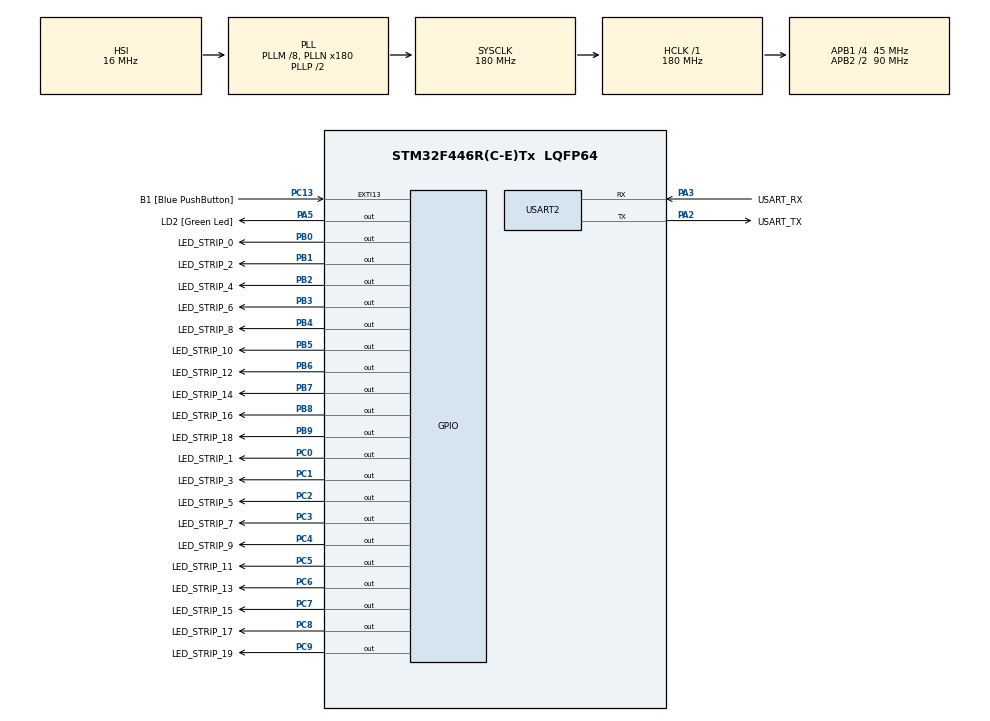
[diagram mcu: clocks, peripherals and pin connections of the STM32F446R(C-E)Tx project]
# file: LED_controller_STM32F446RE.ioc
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Dma.Request0=USART2_RX
Dma.Request1=USART2_TX
Dma.USART2_RX.0.Direction=DMA_PERIPH_TO_MEMORY
Dma.USART2_RX.0.FIFOMode=DMA_FIFOMODE_DISABLE
Dma.USART2_RX.0.Instance=DMA1_Stream5
Dma.USART2_RX.0.MemDataAlignment=DMA_MDATAALIGN_BYTE
Dma.USART2_RX.0.MemInc=DMA_MINC_ENABLE
Dma.USART2_RX.0.Mode=DMA_NORMAL
Dma.USART2_RX.0.PeriphDataAlignment=DMA_PDATAALIGN_BYTE
Dma.USART2_RX.0.PeriphInc=DMA_PINC_DISABLE
Dma.USART2_RX.0.Priority=DMA_PRIORITY_VERY_HIGH
Dma.USART2_TX.1.Direction=DMA_MEMORY_TO_PERIPH
Dma.USART2_TX.1.FIFOMode=DMA_FIFOMODE_DISABLE
Dma.USART2_TX.1.Instance=DMA1_Stream6
Dma.USART2_TX.1.MemDataAlignment=DMA_MDATAALIGN_BYTE
Dma.USART2_TX.1.MemInc=DMA_MINC_ENABLE
Dma.USART2_TX.1.Mode=DMA_NORMAL
Dma.USART2_TX.1.PeriphDataAlignment=DMA_PDATAALIGN_BYTE
Dma.USART2_TX.1.PeriphInc=DMA_PINC_DISABLE
Dma.USART2_TX.1.Priority=DMA_PRIORITY_VERY_HIGH
FREERTOS.Tasks01=defaultTask,0,128,StartDefaultTask,Default,NULL,Dynamic,NULL,NULL
FREERTOS.configCHECK_FOR_STACK_OVERFLOW=1
FREERTOS.configGENERATE_RUN_TIME_STATS=1
FREERTOS.configQUEUE_REGISTRY_SIZE=40
Mcu.Family=STM32F4
Mcu.Name=STM32F446R(C-E)Tx
Mcu.Package=LQFP64
NVIC.DMA1_Stream5_IRQn=true\:5\:0\:false\:false\:true\:true\:false\:true
NVIC.DMA1_Stream6_IRQn=true\:5\:0\:false\:false\:true\:true\:false\:true
NVIC.PriorityGroup=NVIC_PRIORITYGROUP_4
NVIC.TIM3_IRQn=true\:5\:0\:true\:false\:true\:true\:true\:true
NVIC.TIM4_IRQn=true\:0\:0\:false\:false\:true\:false\:false\:true
NVIC.TimeBase=TIM4_IRQn
NVIC.TimeBaseIP=TIM4
PA13.GPIO_Label=TMS
PA13.Mode=Serial_Wire
PA13.Signal=SYS_JTMS-SWDIO
PA14.GPIO_Label=TCK
PA14.Mode=Serial_Wire
PA14.Signal=SYS_JTCK-SWCLK
PA2.GPIO_Label=USART_TX
PA2.Mode=Asynchronous
PA2.Signal=USART2_TX
PA3.GPIO_Label=USART_RX
PA3.Mode=Asynchronous
PA3.Signal=USART2_RX
PA5.GPIO_Label=LD2 [Green Led]
PA5.Signal=GPIO_Output
PB0.GPIO_Label=LED_STRIP_0
PB0.Signal=GPIO_Output
PB1.GPIO_Label=LED_STRIP_2
PB1.Signal=GPIO_Output
PB2.GPIO_Label=LED_STRIP_4
PB2.Signal=GPIO_Output
PB3.GPIO_Label=LED_STRIP_6
PB3.Signal=GPIO_Output
PB4.GPIO_Label=LED_STRIP_8
PB4.Signal=GPIO_Output
PB5.GPIO_Label=LED_STRIP_10
PB5.Signal=GPIO_Output
PB6.GPIO_Label=LED_STRIP_12
PB6.Signal=GPIO_Output
PB7.GPIO_Label=LED_STRIP_14
PB7.Signal=GPIO_Output
PB8.GPIO_Label=LED_STRIP_16
PB8.Signal=GPIO_Output
PB9.GPIO_Label=LED_STRIP_18
PB9.Signal=GPIO_Output
PC0.GPIO_Label=LED_STRIP_1
PC0.Signal=GPIO_Output
PC1.GPIO_Label=LED_STRIP_3
PC1.Signal=GPIO_Output
PC13.GPIO_Label=B1 [Blue PushButton]
PC13.GPIO_ModeDefaultEXTI=GPIO_MODE_IT_FALLING
PC13.Signal=GPXTI13
PC2.GPIO_Label=LED_STRIP_5
PC2.Signal=GPIO_Output
PC3.GPIO_Label=LED_STRIP_7
PC3.Signal=GPIO_Output
PC4.GPIO_Label=LED_STRIP_9
PC4.Signal=GPIO_Output
PC5.GPIO_Label=LED_STRIP_11
PC5.Signal=GPIO_Output
PC6.GPIO_Label=LED_STRIP_13
PC6.Signal=GPIO_Output
PC7.GPIO_Label=LED_STRIP_15
PC7.Signal=GPIO_Output
PC8.GPIO_Label=LED_STRIP_17
PC8.Signal=GPIO_Output
PC9.GPIO_Label=LED_STRIP_19
PC9.Signal=GPIO_Output
ProjectManager.HeapSize=0x200
ProjectManager.StackSize=0x400
ProjectManager.TargetToolchain=STM32CubeIDE
RCC.48MHZClocksFreq_Value=84000000
RCC.AHBFreq_Value=180000000
RCC.APB1CLKDivider=RCC_HCLK_DIV4
RCC.APB1Freq_Value=45000000
RCC.APB1TimFreq_Value=90000000
RCC.APB2CLKDivider=RCC_HCLK_DIV2
RCC.APB2Freq_Value=90000000
RCC.APB2TimFreq_Value=180000000
RCC.CortexFreq_Value=180000000
RCC.FLatency-AdvancedSettings=FLASH_LATENCY_5
RCC.HCLKFreq_Value=180000000
RCC.HSE_VALUE=8000000
RCC.HSI_VALUE=16000000
RCC.PLLM=8
RCC.PLLN=180
RCC.SYSCLKFreq_VALUE=180000000
RCC.SYSCLKSource=RCC_SYSCLKSOURCE_PLLCLK
RCC.USBFreq_Value=180000000
RCC.VCOOutputFreq_Value=360000000
TIM3.Period=79
TIM3.Prescaler=44999
USART2.VirtualMode=VM_ASYNC
VP_FREERTOS_VS_CMSIS_V1.Mode=CMSIS_V1
VP_SYS_VS_tim4.Mode=TIM4
VP_TIM3_VS_ClockSourceINT.Mode=Internal
board=NUCLEO-F446RE

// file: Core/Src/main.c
/* USER CODE BEGIN Header */
/**
  ******************************************************************************
  * @file           : main.c
  * @brief          : Main program body
  ******************************************************************************
  * @attention
  *
  * <h2><center>&copy; Copyright (c) 2020 STMicroelectronics.
  * All rights reserved.</center></h2>
  *
  * This software component is licensed by ST under Ultimate Liberty license
  * SLA0044, the "License"; You may not use this file except in compliance with
  * the License. You may obtain a copy of the License at:
  *                             www.st.com/SLA0044
  *
  ******************************************************************************
  */
/* USER CODE END Header */
#include "main.h"
#include "cmsis_os.h"
#include "dma.h"
#include "tim.h"
#include "usart.h"
#include "gpio.h"

/* USER CODE BEGIN Includes */
#include "porting_layer.h"
#include "ws2812b_multi_strip_driver.h"
/* USER CODE END Includes */

void SystemClock_Config(void);
void MX_FREERTOS_Init(void);

int main(void)
{

  /* MCU Configuration--------------------------------------------------------*/

  /* Reset of all peripherals, Initializes the Flash interface and the Systick. */
  HAL_Init();

  /* Configure the system clock */
  SystemClock_Config();

  /* Initialize all configured peripherals */
  MX_GPIO_Init();
  MX_DMA_Init();
  MX_USART2_UART_Init();
  MX_TIM3_Init();

  /* Call init function for freertos objects (in freertos.c) */
  MX_FREERTOS_Init();
  /* Start scheduler */
  osKernelStart();

  /* We should never get here as control is now taken by the scheduler */
  /* Infinite loop */
  while (1)
  {

  }
}

void SystemClock_Config(void)
{
  RCC_OscInitTypeDef RCC_OscInitStruct = {0};
  RCC_ClkInitTypeDef RCC_ClkInitStruct = {0};

  /** Configure the main internal regulator output voltage
  */
  __HAL_RCC_PWR_CLK_ENABLE();
  __HAL_PWR_VOLTAGESCALING_CONFIG(PWR_REGULATOR_VOLTAGE_SCALE1);
  /** Initializes the RCC Oscillators according to the specified parameters
  * in the RCC_OscInitTypeDef structure.
  */
  RCC_OscInitStruct.OscillatorType = RCC_OSCILLATORTYPE_HSI;
  RCC_OscInitStruct.HSIState = RCC_HSI_ON;
  RCC_OscInitStruct.HSICalibrationValue = RCC_HSICALIBRATION_DEFAULT;
  RCC_OscInitStruct.PLL.PLLState = RCC_PLL_ON;
  RCC_OscInitStruct.PLL.PLLSource = RCC_PLLSOURCE_HSI;
  RCC_OscInitStruct.PLL.PLLM = 8;
  RCC_OscInitStruct.PLL.PLLN = 180;
  RCC_OscInitStruct.PLL.PLLP = RCC_PLLP_DIV2;
  RCC_OscInitStruct.PLL.PLLQ = 2;
  RCC_OscInitStruct.PLL.PLLR = 2;
  if (HAL_RCC_OscConfig(&RCC_OscInitStruct) != HAL_OK)
  {
    Error_Handler();
  }
  /** Activate the Over-Drive mode
  */
  if (HAL_PWREx_EnableOverDrive() != HAL_OK)
  {
    Error_Handler();
  }
  /** Initializes the CPU, AHB and APB buses clocks
  */
  RCC_ClkInitStruct.ClockType = RCC_CLOCKTYPE_HCLK|RCC_CLOCKTYPE_SYSCLK
                              |RCC_CLOCKTYPE_PCLK1|RCC_CLOCKTYPE_PCLK2;
  RCC_ClkInitStruct.SYSCLKSource = RCC_SYSCLKSOURCE_PLLCLK;
  RCC_ClkInitStruct.AHBCLKDivider = RCC_SYSCLK_DIV1;
  RCC_ClkInitStruct.APB1CLKDivider = RCC_HCLK_DIV4;
  RCC_ClkInitStruct.APB2CLKDivider = RCC_HCLK_DIV2;

  if (HAL_RCC_ClockConfig(&RCC_ClkInitStruct, FLASH_LATENCY_5) != HAL_OK)
  {
    Error_Handler();
  }
}

void HAL_TIM_PeriodElapsedCallback(TIM_HandleTypeDef *htim)
{
  if (htim->Instance == TIM4) {
    HAL_IncTick();
  }
  /* USER CODE BEGIN Callback 1 */
  else if (htim->Instance == TIM3)
  {
      pl_start_frame_timer();
      start_led_driver_run();
  }
  /* USER CODE END Callback 1 */
}

void Error_Handler(void)
{
}

/************************ (C) COPYRIGHT STMicroelectronics *****END OF FILE****/

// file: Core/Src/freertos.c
/* USER CODE BEGIN Header */
/**
  ******************************************************************************
  * File Name          : freertos.c
  * Description        : Code for freertos applications
  ******************************************************************************
  * @attention
  *
  * <h2><center>&copy; Copyright (c) 2020 STMicroelectronics.
  * All rights reserved.</center></h2>
  *
  * This software component is licensed by ST under Ultimate Liberty license
  * SLA0044, the "License"; You may not use this file except in compliance with
  * the License. You may obtain a copy of the License at:
  *                             www.st.com/SLA0044
  *
  ******************************************************************************
  */
/* USER CODE END Header */

#include "FreeRTOS.h"
#include "task.h"
#include "main.h"
#include "cmsis_os.h"

/* USER CODE BEGIN Includes */
#include "ws2812b_multi_strip_driver.h"
#include "shows.h"
#include "scheduler.h"
/* USER CODE END Includes */

osThreadId defaultTaskHandle;

void StartDefaultTask(void const * argument);

void MX_FREERTOS_Init(void); /* (MISRA C 2004 rule 8.1) */

/* GetIdleTaskMemory prototype (linked to static allocation support) */
void vApplicationGetIdleTaskMemory( StaticTask_t **ppxIdleTaskTCBBuffer, StackType_t **ppxIdleTaskStackBuffer, uint32_t *pulIdleTaskStackSize );

/* Hook prototypes */
void configureTimerForRunTimeStats(void);
unsigned long getRunTimeCounterValue(void);
void vApplicationStackOverflowHook(xTaskHandle xTask, signed char *pcTaskName);

/* USER CODE BEGIN 1 */
/* Functions needed when configGENERATE_RUN_TIME_STATS is on */
__weak void configureTimerForRunTimeStats(void)
{

}

__weak unsigned long getRunTimeCounterValue(void)
{
return 0;
}
/* USER CODE END 1 */

/* USER CODE BEGIN 4 */
__weak void vApplicationStackOverflowHook(xTaskHandle xTask, signed char *pcTaskName)
{
   /* Run time stack overflow checking is performed if
   configCHECK_FOR_STACK_OVERFLOW is defined to 1 or 2. This hook function is
   called if a stack overflow is detected. */
}
/* USER CODE END 4 */

/* USER CODE BEGIN GET_IDLE_TASK_MEMORY */
static StaticTask_t xIdleTaskTCBBuffer;
static StackType_t xIdleStack[configMINIMAL_STACK_SIZE];

void vApplicationGetIdleTaskMemory( StaticTask_t **ppxIdleTaskTCBBuffer, StackType_t **ppxIdleTaskStackBuffer, uint32_t *pulIdleTaskStackSize )
{
  *ppxIdleTaskTCBBuffer = &xIdleTaskTCBBuffer;
  *ppxIdleTaskStackBuffer = &xIdleStack[0];
  *pulIdleTaskStackSize = configMINIMAL_STACK_SIZE;
  /* place for user code */
}
/* USER CODE END GET_IDLE_TASK_MEMORY */

void MX_FREERTOS_Init(void) {
  /* USER CODE BEGIN Init */
  init_led_driver_rtos_resources();
  init_shows_rtos_resources();
  init_scheduler_rtos_resources();
  /* USER CODE END Init */

  /* Create the thread(s) */
  /* definition and creation of defaultTask */
  osThreadDef(defaultTask, StartDefaultTask, osPriorityNormal, 0, 128);
  defaultTaskHandle = osThreadCreate(osThread(defaultTask), NULL);

  /* USER CODE BEGIN RTOS_THREADS */
  init_led_driver_tasks();
  init_shows_tasks();
  init_scheduler_tasks();
  /* USER CODE END RTOS_THREADS */

}

void StartDefaultTask(void const * argument)
{
  for(;;)
  {
    osDelay(1);
  }
}

/************************ (C) COPYRIGHT STMicroelectronics *****END OF FILE****/
